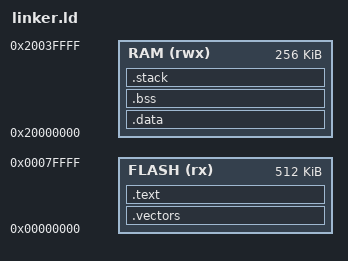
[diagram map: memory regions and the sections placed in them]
ENTRY(_start)

MEMORY
{
    FLASH (rx)  : ORIGIN = 0x00000000, LENGTH = 512K
    RAM   (rwx) : ORIGIN = 0x20000000, LENGTH = 256K
}

_stack_size = 0x1000;

SECTIONS
{
    .vectors :
    {
        KEEP(*(.vectors))
    } > FLASH

    .text :
    {
        *(.text*)
        *(.rodata*)
    } > FLASH

    .data : AT (ADDR(.text) + SIZEOF(.text))
    {
        __data_start__ = .;
        *(.data*)
        __data_end__ = .;
    } > RAM

    .bss :
    {
        __bss_start__ = .;
        *(.bss*)
        *(COMMON)
        __bss_end__ = .;
    } > RAM

    .stack (NOLOAD):
    {
        . = ALIGN(8);
        _stack_top = . + _stack_size;
    } > RAM
}

